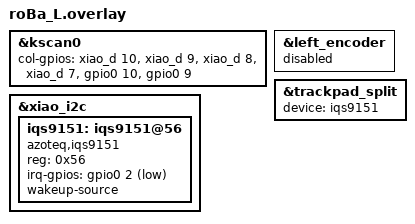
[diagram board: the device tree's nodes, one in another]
#include "roBa.dtsi"

&kscan0 {
        col-gpios
            = <&xiao_d 10 GPIO_ACTIVE_HIGH>
            , <&xiao_d 9 GPIO_ACTIVE_HIGH> 
            , <&xiao_d 8 GPIO_ACTIVE_HIGH> 
            , <&xiao_d 7 GPIO_ACTIVE_HIGH> 
            , <&gpio0 10 GPIO_ACTIVE_HIGH>
            , <&gpio0 9 GPIO_ACTIVE_HIGH>
            ;
};

&left_encoder {
    status = "disabled";
};

&xiao_i2c {
    status = "okay";

    iqs9151: iqs9151@56 {
        compatible = "azoteq,iqs9151";
        reg = <0x56>;
        status = "okay";
        irq-gpios = <&gpio0 2 (GPIO_ACTIVE_LOW | GPIO_PULL_UP)>;
        wakeup-source;
    };
};

&trackpad_split {
    device = <&iqs9151>;
};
